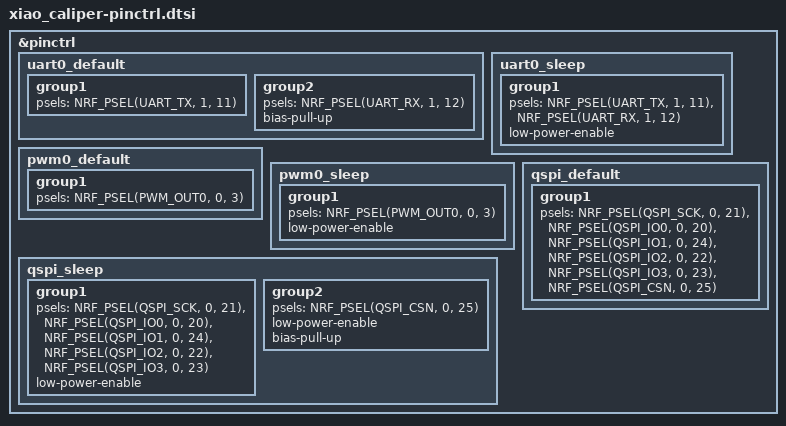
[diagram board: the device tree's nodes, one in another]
/*
 * Copyright (c) 2022 Marcin Niestroj
 * Copyright (c) 2026 Robin Callender
 * SPDX-License-Identifier: Apache-2.0
 */

&pinctrl {
	uart0_default: uart0_default {
		group1 {
			psels = <NRF_PSEL(UART_TX, 1, 11)>;
		};

		group2 {
			psels = <NRF_PSEL(UART_RX, 1, 12)>;
			bias-pull-up;
		};
	};

	uart0_sleep: uart0_sleep {
		group1 {
			psels = <NRF_PSEL(UART_TX, 1, 11)>,
				<NRF_PSEL(UART_RX, 1, 12)>;
			low-power-enable;
		};
	};

#if 0
	i2c1_default: i2c1_default {
		group1 {
			psels = <NRF_PSEL(TWIM_SDA, 0, 4)>,
				<NRF_PSEL(TWIM_SCL, 0, 5)>;
		};
	};

	i2c1_sleep: i2c1_sleep {
		group1 {
			psels = <NRF_PSEL(TWIM_SDA, 0, 4)>,
				<NRF_PSEL(TWIM_SCL, 0, 5)>;
			low-power-enable;
		};
	};
#endif	

	/*
	 * Buzzer drive: PWM_OUT0 -> BUZZ net -> gate of Q1 (N-FET, R1 pull-down).
	 * BUZZ = P0.03 (XIAO D1). Output idles LOW (FET off), so no invert.
	 */
	pwm0_default: pwm0_default {
		group1 {
			psels = <NRF_PSEL(PWM_OUT0, 0, 3)>;
		};
	};

	pwm0_sleep: pwm0_sleep {
		group1 {
			psels = <NRF_PSEL(PWM_OUT0, 0, 3)>;
			low-power-enable;
		};
	};

#if 0
	spi2_default: spi2_default {
		group1 {
			psels = <NRF_PSEL(SPIM_SCK, 1, 13)>,
				<NRF_PSEL(SPIM_MOSI, 1, 15)>,
				<NRF_PSEL(SPIM_MISO, 1, 14)>;
		};
	};

	spi2_sleep: spi2_sleep {
		group1 {
			psels = <NRF_PSEL(SPIM_SCK, 1, 13)>,
				<NRF_PSEL(SPIM_MOSI, 1, 15)>,
				<NRF_PSEL(SPIM_MISO, 1, 14)>;
			low-power-enable;
		};
	};
#endif

	qspi_default: qspi_default {
		group1 {
			psels = <NRF_PSEL(QSPI_SCK, 0, 21)>,
				<NRF_PSEL(QSPI_IO0, 0, 20)>,
				<NRF_PSEL(QSPI_IO1, 0, 24)>,
				<NRF_PSEL(QSPI_IO2, 0, 22)>,
				<NRF_PSEL(QSPI_IO3, 0, 23)>,
				<NRF_PSEL(QSPI_CSN, 0, 25)>;
		};
	};

	qspi_sleep: qspi_sleep {
		group1 {
			psels = <NRF_PSEL(QSPI_SCK, 0, 21)>,
				<NRF_PSEL(QSPI_IO0, 0, 20)>,
				<NRF_PSEL(QSPI_IO1, 0, 24)>,
				<NRF_PSEL(QSPI_IO2, 0, 22)>,
				<NRF_PSEL(QSPI_IO3, 0, 23)>;
			low-power-enable;
		};

		group2 {
			psels = <NRF_PSEL(QSPI_CSN, 0, 25)>;
			low-power-enable;
			bias-pull-up;
		};
	};
};
